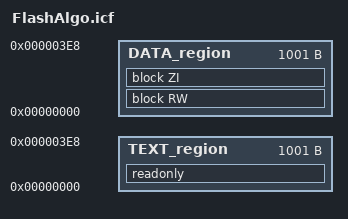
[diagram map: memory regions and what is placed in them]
; Flash OS Routines
; Copyright (c) 2009-2015 ARM Limited
;
; Licensed under the Apache License, Version 2.0 (the "License");
; you may not use this file except in compliance with the License.
; You may obtain a copy of the License at
;
;     http://www.apache.org/licenses/LICENSE-2.0
;
; Unless required by applicable law or agreed to in writing, software
; distributed under the License is distributed on an "AS IS" BASIS,
; WITHOUT WARRANTIES OR CONDITIONS OF ANY KIND, either express or implied.
; See the License for the specific language governing permissions and
; limitations under the License.


define memory mem with size = 4G;
define region TEXT_region = mem:[from 0 to 1000];
define region DATA_region = mem:[from 0 to 1000];
define region DevDscr;

define block RW        { readwrite };
define block ZI        { zi };


place in TEXT_region                        { readonly };
place in DATA_region                        { block RW };
place in DATA_region                        { block ZI };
